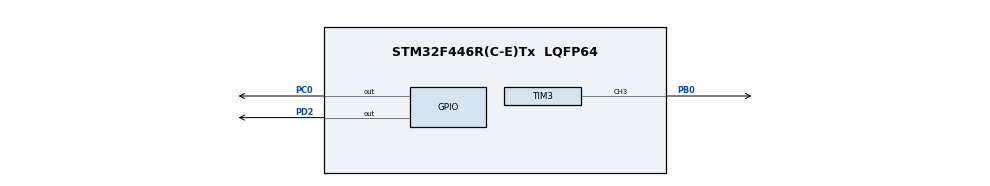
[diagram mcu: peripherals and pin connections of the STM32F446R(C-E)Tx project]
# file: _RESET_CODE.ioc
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Dma.Request0=TIM3_CH3
Dma.TIM3_CH3.0.Direction=DMA_MEMORY_TO_PERIPH
Dma.TIM3_CH3.0.FIFOMode=DMA_FIFOMODE_DISABLE
Dma.TIM3_CH3.0.Instance=DMA1_Stream7
Dma.TIM3_CH3.0.MemDataAlignment=DMA_MDATAALIGN_HALFWORD
Dma.TIM3_CH3.0.MemInc=DMA_MINC_ENABLE
Dma.TIM3_CH3.0.Mode=DMA_CIRCULAR
Dma.TIM3_CH3.0.PeriphDataAlignment=DMA_PDATAALIGN_HALFWORD
Dma.TIM3_CH3.0.PeriphInc=DMA_PINC_DISABLE
Dma.TIM3_CH3.0.Priority=DMA_PRIORITY_VERY_HIGH
Mcu.Family=STM32F4
Mcu.Name=STM32F446R(C-E)Tx
Mcu.Package=LQFP64
NVIC.DMA1_Stream7_IRQn=true\:0\:0\:false\:false\:true\:false\:true\:true
NVIC.PriorityGroup=NVIC_PRIORITYGROUP_4
PB0.Signal=S_TIM3_CH3
PC0.Signal=GPIO_Output
PD2.Signal=GPIO_Output
ProjectManager.HeapSize=0x200
ProjectManager.StackSize=0x400
ProjectManager.TargetToolchain=STM32CubeIDE
RCC.CortexFreq_Value=16000000
RCC.USBFreq_Value=96000000
RCC.VCOOutputFreq_Value=192000000
SH.S_TIM3_CH3.0=TIM3_CH3,PWM Generation3 CH3
TIM3.AutoReloadPreload=TIM_AUTORELOAD_PRELOAD_ENABLE
TIM3.Channel-PWM\ Generation3\ CH3=TIM_CHANNEL_3
TIM3.Period=20
VP_TIM3_VS_ClockSourceINT.Mode=Internal
board=custom

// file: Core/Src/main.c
/* USER CODE BEGIN Header */
/**
  ******************************************************************************
  * @file           : main.c
  * @brief          : Main program body
  ******************************************************************************
  * @attention
  *
  * Copyright (c) 2024 STMicroelectronics.
  * All rights reserved.
  *
  * This software is licensed under terms that can be found in the LICENSE file
  * in the root directory of this software component.
  * If no LICENSE file comes with this software, it is provided AS-IS.
  *
  ******************************************************************************
  */
/* USER CODE END Header */
#include "main.h"

TIM_HandleTypeDef htim3;
DMA_HandleTypeDef hdma_tim3_ch3;

void SystemClock_Config(void);
static void MX_GPIO_Init(void);
static void MX_DMA_Init(void);
static void MX_TIM3_Init(void);

int main(void)
{

  /* MCU Configuration--------------------------------------------------------*/

  /* Reset of all peripherals, Initializes the Flash interface and the Systick. */
  HAL_Init();

  /* Configure the system clock */
  SystemClock_Config();

  /* Initialize all configured peripherals */
  MX_GPIO_Init();
  MX_DMA_Init();
  MX_TIM3_Init();
  /* USER CODE BEGIN 2 */
  HAL_GPIO_WritePin( GPIOC, GPIO_PIN_0, GPIO_PIN_SET);
  HAL_GPIO_WritePin( GPIOD, GPIO_PIN_2, GPIO_PIN_SET);
  /* USER CODE END 2 */

  /* Infinite loop */
  while (1)
  {

  }
}

void SystemClock_Config(void)
{
  RCC_OscInitTypeDef RCC_OscInitStruct = {0};
  RCC_ClkInitTypeDef RCC_ClkInitStruct = {0};

  /** Configure the main internal regulator output voltage
  */
  __HAL_RCC_PWR_CLK_ENABLE();
  __HAL_PWR_VOLTAGESCALING_CONFIG(PWR_REGULATOR_VOLTAGE_SCALE3);

  /** Initializes the RCC Oscillators according to the specified parameters
  * in the RCC_OscInitTypeDef structure.
  */
  RCC_OscInitStruct.OscillatorType = RCC_OSCILLATORTYPE_HSI;
  RCC_OscInitStruct.HSIState = RCC_HSI_ON;
  RCC_OscInitStruct.HSICalibrationValue = RCC_HSICALIBRATION_DEFAULT;
  RCC_OscInitStruct.PLL.PLLState = RCC_PLL_NONE;
  if (HAL_RCC_OscConfig(&RCC_OscInitStruct) != HAL_OK)
  {
    Error_Handler();
  }

  /** Initializes the CPU, AHB and APB buses clocks
  */
  RCC_ClkInitStruct.ClockType = RCC_CLOCKTYPE_HCLK|RCC_CLOCKTYPE_SYSCLK
                              |RCC_CLOCKTYPE_PCLK1|RCC_CLOCKTYPE_PCLK2;
  RCC_ClkInitStruct.SYSCLKSource = RCC_SYSCLKSOURCE_HSI;
  RCC_ClkInitStruct.AHBCLKDivider = RCC_SYSCLK_DIV1;
  RCC_ClkInitStruct.APB1CLKDivider = RCC_HCLK_DIV1;
  RCC_ClkInitStruct.APB2CLKDivider = RCC_HCLK_DIV1;

  if (HAL_RCC_ClockConfig(&RCC_ClkInitStruct, FLASH_LATENCY_0) != HAL_OK)
  {
    Error_Handler();
  }
}

static void MX_TIM3_Init(void)
{

  TIM_ClockConfigTypeDef sClockSourceConfig = {0};
  TIM_MasterConfigTypeDef sMasterConfig = {0};
  TIM_OC_InitTypeDef sConfigOC = {0};

  htim3.Instance = TIM3;
  htim3.Init.Prescaler = 0;
  htim3.Init.CounterMode = TIM_COUNTERMODE_UP;
  htim3.Init.Period = 20;
  htim3.Init.ClockDivision = TIM_CLOCKDIVISION_DIV1;
  htim3.Init.AutoReloadPreload = TIM_AUTORELOAD_PRELOAD_ENABLE;
  if (HAL_TIM_Base_Init(&htim3) != HAL_OK)
  {
    Error_Handler();
  }
  sClockSourceConfig.ClockSource = TIM_CLOCKSOURCE_INTERNAL;
  if (HAL_TIM_ConfigClockSource(&htim3, &sClockSourceConfig) != HAL_OK)
  {
    Error_Handler();
  }
  if (HAL_TIM_PWM_Init(&htim3) != HAL_OK)
  {
    Error_Handler();
  }
  sMasterConfig.MasterOutputTrigger = TIM_TRGO_RESET;
  sMasterConfig.MasterSlaveMode = TIM_MASTERSLAVEMODE_DISABLE;
  if (HAL_TIMEx_MasterConfigSynchronization(&htim3, &sMasterConfig) != HAL_OK)
  {
    Error_Handler();
  }
  sConfigOC.OCMode = TIM_OCMODE_PWM1;
  sConfigOC.Pulse = 0;
  sConfigOC.OCPolarity = TIM_OCPOLARITY_HIGH;
  sConfigOC.OCFastMode = TIM_OCFAST_DISABLE;
  if (HAL_TIM_PWM_ConfigChannel(&htim3, &sConfigOC, TIM_CHANNEL_3) != HAL_OK)
  {
    Error_Handler();
  }
  HAL_TIM_MspPostInit(&htim3);

}

static void MX_DMA_Init(void)
{

  /* DMA controller clock enable */
  __HAL_RCC_DMA1_CLK_ENABLE();

  /* DMA interrupt init */
  /* DMA1_Stream7_IRQn interrupt configuration */
  HAL_NVIC_SetPriority(DMA1_Stream7_IRQn, 0, 0);
  HAL_NVIC_EnableIRQ(DMA1_Stream7_IRQn);

}

static void MX_GPIO_Init(void)
{
  GPIO_InitTypeDef GPIO_InitStruct = {0};

  /* GPIO Ports Clock Enable */
  __HAL_RCC_GPIOC_CLK_ENABLE();
  __HAL_RCC_GPIOB_CLK_ENABLE();
  __HAL_RCC_GPIOD_CLK_ENABLE();

  /*Configure GPIO pin Output Level */
  HAL_GPIO_WritePin(GPIOC, GPIO_PIN_0, GPIO_PIN_RESET);

  /*Configure GPIO pin Output Level */
  HAL_GPIO_WritePin(GPIOD, GPIO_PIN_2, GPIO_PIN_RESET);

  /*Configure GPIO pin : PC0 */
  GPIO_InitStruct.Pin = GPIO_PIN_0;
  GPIO_InitStruct.Mode = GPIO_MODE_OUTPUT_PP;
  GPIO_InitStruct.Pull = GPIO_NOPULL;
  GPIO_InitStruct.Speed = GPIO_SPEED_FREQ_LOW;
  HAL_GPIO_Init(GPIOC, &GPIO_InitStruct);

  /*Configure GPIO pin : PD2 */
  GPIO_InitStruct.Pin = GPIO_PIN_2;
  GPIO_InitStruct.Mode = GPIO_MODE_OUTPUT_PP;
  GPIO_InitStruct.Pull = GPIO_NOPULL;
  GPIO_InitStruct.Speed = GPIO_SPEED_FREQ_LOW;
  HAL_GPIO_Init(GPIOD, &GPIO_InitStruct);

}

void Error_Handler(void)
{
  __disable_irq();
  while (1)
  {
  }
}
